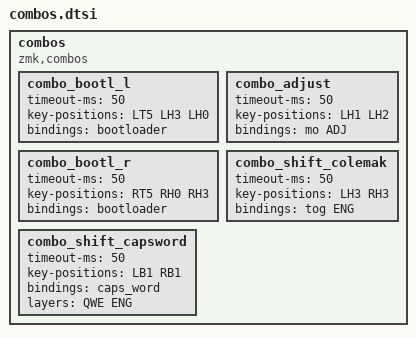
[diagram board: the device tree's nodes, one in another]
/* 58 KEY MATRIX / LAYOUT MAPPING
 ╭────────────────────────────┬────────────────────────────╮
 │  0   1   2   3   4   5     │      6   7   8   9  10  11 │
 │ 12  13  14  15  16  17     │     18  19  20  21  22  23 │
 │ 24  25  26  27  28  29     │     30  31  32  33  34  35 │
 │ 36  37  38  39  40  41  42 │ 43  44  45  46  47  48  49 │
 ╰───────────╮ 50  51  52  53 │ 54  55  56  57 ╭───────────╯
             ╰────────────────┴────────────────╯
╭─────────────────────────────┬─────────────────────────────╮
│ LT5 LT4 LT3 LT2 LT1 LT0     │     RT0 RT1 RT2 RT3 RT4 RT5 │
│ LM5 LM4 LM3 LM2 LM1 LM0     │     RM0 RM1 RM2 RM3 RM4 RM5 │
│ LB5 LB4 LB3 LB2 LB1 LB0     │     RB0 RB1 RB2 RB3 RB4 RB5 │
│ LF5 LF4 LF3 LF2 LF1 LF0 LEC │ REC RF0 RF1 RF2 RF3 RF4 RF5 │
╰───────────╮ LH3 LH2 LH1 LH0 │ RH0 RH1 RH2 RH3 ╭───────────╯
            ╰─────────────────┴─────────────────╯
  */
combos {
    compatible = "zmk,combos";
    combo_bootl_l {
        timeout-ms = <50>;
        key-positions = <LT5 LH3 LH0>;
        bindings = <&bootloader>;
    };
    combo_bootl_r {
        timeout-ms = <50>;
        key-positions = <RT5 RH0 RH3>;
        bindings = <&bootloader>;
    };
    combo_adjust {
        timeout-ms = <50>;
        key-positions = <LH1 LH2>;
        bindings = <&mo ADJ>;
    };
    combo_shift_capsword {
        timeout-ms = <50>;
        key-positions = <LB1 RB1>;
        bindings = <&caps_word>;
        layers = <QWE ENG>;
    };
    combo_shift_colemak {
        timeout-ms = <50>;
        key-positions = <LH3 RH3>;
        bindings = <&tog ENG>;
    };
};
